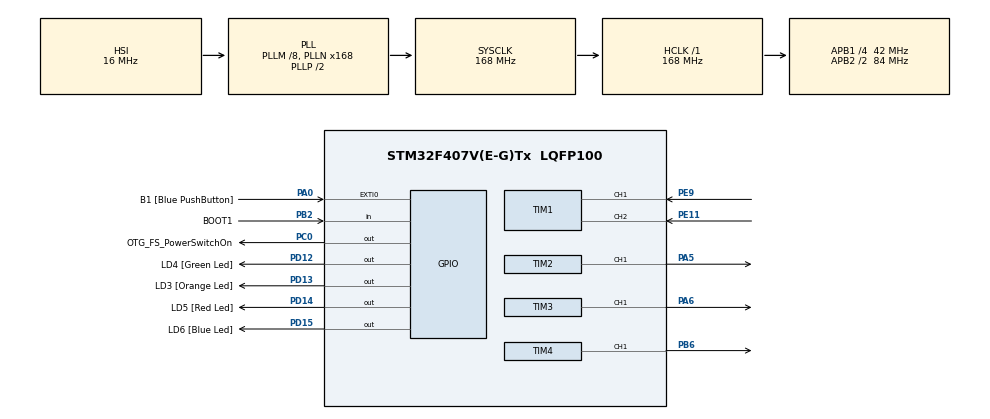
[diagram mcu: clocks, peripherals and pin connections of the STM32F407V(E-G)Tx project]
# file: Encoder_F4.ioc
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Mcu.Family=STM32F4
Mcu.Name=STM32F407V(E-G)Tx
Mcu.Package=LQFP100
NVIC.PriorityGroup=NVIC_PRIORITYGROUP_0
NVIC.TIM1_BRK_TIM9_IRQn=true\:0\:0\:false\:false\:true\:true\:true\:true
NVIC.TIM1_CC_IRQn=true\:0\:0\:false\:false\:true\:true\:true\:true
NVIC.TIM1_TRG_COM_TIM11_IRQn=true\:0\:0\:false\:false\:true\:true\:true\:true
NVIC.TIM1_UP_TIM10_IRQn=true\:0\:0\:false\:false\:true\:true\:true\:true
PA0-WKUP.GPIO_Label=B1 [Blue PushButton]
PA0-WKUP.Signal=GPXTI0
PA13.GPIO_Label=SWDIO
PA13.Signal=SYS_JTMS-SWDIO
PA14.GPIO_Label=SWCLK
PA14.Signal=SYS_JTCK-SWCLK
PA5.Signal=S_TIM2_CH1_ETR
PA6.Signal=S_TIM3_CH1
PB2.GPIO_Label=BOOT1
PB2.GPIO_Mode=GPIO_MODE_INPUT
PB2.GPIO_PuPd=GPIO_NOPULL
PB2.Signal=GPIO_Input
PB3.GPIO_Label=SWO
PB3.Signal=SYS_JTDO-SWO
PB6.Signal=S_TIM4_CH1
PC0.GPIO_Label=OTG_FS_PowerSwitchOn
PC0.GPIO_PuPd=GPIO_NOPULL
PC0.GPIO_Speed=GPIO_SPEED_FREQ_LOW
PC0.PinState=GPIO_PIN_SET
PC0.Signal=GPIO_Output
PD12.GPIO_Label=LD4 [Green Led]
PD12.GPIO_PuPd=GPIO_NOPULL
PD12.GPIO_Speed=GPIO_SPEED_FREQ_LOW
PD12.Signal=GPIO_Output
PD13.GPIO_Label=LD3 [Orange Led]
PD13.GPIO_PuPd=GPIO_NOPULL
PD13.GPIO_Speed=GPIO_SPEED_FREQ_LOW
PD13.Signal=GPIO_Output
PD14.GPIO_Label=LD5 [Red Led]
PD14.GPIO_PuPd=GPIO_NOPULL
PD14.GPIO_Speed=GPIO_SPEED_FREQ_LOW
PD14.Signal=GPIO_Output
PD15.GPIO_Label=LD6 [Blue Led]
PD15.GPIO_PuPd=GPIO_NOPULL
PD15.GPIO_Speed=GPIO_SPEED_FREQ_LOW
PD15.Signal=GPIO_Output
PE11.Signal=S_TIM1_CH2
PE9.Signal=S_TIM1_CH1
PH0-OSC_IN.GPIO_Label=PH0-OSC_IN
PH0-OSC_IN.Mode=HSE-External-Oscillator
PH0-OSC_IN.Signal=RCC_OSC_IN
PH1-OSC_OUT.GPIO_Label=PH1-OSC_OUT
PH1-OSC_OUT.Mode=HSE-External-Oscillator
PH1-OSC_OUT.Signal=RCC_OSC_OUT
ProjectManager.HeapSize=0x200
ProjectManager.StackSize=0x400
ProjectManager.TargetToolchain=STM32CubeIDE
RCC.48MHZClocksFreq_Value=48000000
RCC.AHBFreq_Value=168000000
RCC.APB1CLKDivider=RCC_HCLK_DIV4
RCC.APB1Freq_Value=42000000
RCC.APB1TimFreq_Value=84000000
RCC.APB2CLKDivider=RCC_HCLK_DIV2
RCC.APB2Freq_Value=84000000
RCC.APB2TimFreq_Value=168000000
RCC.CortexFreq_Value=168000000
RCC.HCLKFreq_Value=168000000
RCC.HSE_VALUE=8000000
RCC.HSI_VALUE=16000000
RCC.LSE_VALUE=32768
RCC.PLLM=8
RCC.PLLN=168
RCC.PLLQ=7
RCC.SYSCLKFreq_VALUE=168000000
RCC.SYSCLKSource=RCC_SYSCLKSOURCE_PLLCLK
RCC.VCOOutputFreq_Value=336000000
SH.S_TIM1_CH1.0=TIM1_CH1,Encoder_Interface
SH.S_TIM1_CH2.0=TIM1_CH2,Encoder_Interface
SH.S_TIM2_CH1_ETR.0=TIM2_CH1,PWM Generation1 CH1
SH.S_TIM3_CH1.0=TIM3_CH1,PWM Generation1 CH1
SH.S_TIM4_CH1.0=TIM4_CH1,PWM Generation1 CH1
TIM1.AutoReloadPreload=TIM_AUTORELOAD_PRELOAD_ENABLE
TIM1.EncoderMode=TIM_ENCODERMODE_TI12
TIM1.IC1Filter=10
TIM1.IC1Polarity=TIM_ICPOLARITY_FALLING
TIM1.IC2Filter=10
TIM1.IC2Polarity=TIM_ICPOLARITY_FALLING
TIM2.Channel-Output\ Compare2\ No\ Output=TIM_CHANNEL_2
TIM2.Channel-PWM\ Generation1\ CH1=TIM_CHANNEL_1
TIM2.OCMode_2=TIM_OCMODE_ACTIVE
TIM2.Period=10000-1
TIM2.Prescaler=168-1
TIM2.Pulse-Output\ Compare2\ No\ Output=2500
TIM2.Pulse-PWM\ Generation1\ CH1=5000
TIM2.TIM_MasterOutputTrigger=TIM_TRGO_OC2REF
TIM3.Channel-Output\ Compare2\ No\ Output=TIM_CHANNEL_2
TIM3.Channel-PWM\ Generation1\ CH1=TIM_CHANNEL_1
TIM3.OCMode_2=TIM_OCMODE_ACTIVE
TIM3.Period=10000-1
TIM3.Prescaler=168-1
TIM3.Pulse-Output\ Compare2\ No\ Output=2500
TIM3.Pulse-PWM\ Generation1\ CH1=5000
TIM3.TIM_MasterOutputTrigger=TIM_TRGO_OC2REF
TIM4.Channel-PWM\ Generation1\ CH1=TIM_CHANNEL_1
TIM4.Period=10000-1
TIM4.Prescaler=168-1
TIM4.Pulse-PWM\ Generation1\ CH1=5000
TIM4.TIM_MasterOutputTrigger=TIM_TRGO_RESET
VP_TIM2_VS_ClockSourceINT.Mode=Internal
VP_TIM2_VS_no_output2.Mode=Output Compare2 No Output
VP_TIM3_VS_ClockSourceITR.Mode=TriggerSource_ITR1
VP_TIM3_VS_ControllerModeTrigger.Mode=Trigger Mode
VP_TIM3_VS_no_output2.Mode=Output Compare2 No Output
VP_TIM4_VS_ClockSourceITR.Mode=TriggerSource_ITR2
VP_TIM4_VS_ControllerModeTrigger.Mode=Trigger Mode
board=STM32F407G-DISC1

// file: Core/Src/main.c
/* USER CODE BEGIN Header */
/**
  ******************************************************************************
  * @file           : main.c
  * @brief          : Main program body
  ******************************************************************************
  * @attention
  *
  * Copyright (c) 2023 STMicroelectronics.
  * All rights reserved.
  *
  * This software is licensed under terms that can be found in the LICENSE file
  * in the root directory of this software component.
  * If no LICENSE file comes with this software, it is provided AS-IS.
  *
  ******************************************************************************
  */
/* USER CODE END Header */
#include "main.h"

/* USER CODE BEGIN PD */
	uint32_t counter=0;
	int16_t count=0,position=0;
	int16_t speed=0;
/* USER CODE END PD */

TIM_HandleTypeDef htim1;
TIM_HandleTypeDef htim2;
TIM_HandleTypeDef htim3;
TIM_HandleTypeDef htim4;

void SystemClock_Config(void);
static void MX_GPIO_Init(void);
static void MX_TIM1_Init(void);
static void MX_TIM2_Init(void);
static void MX_TIM3_Init(void);
static void MX_TIM4_Init(void);
/* USER CODE BEGIN PFP */
void HAL_TIM_IC_CaptureCallback(TIM_HandleTypeDef *htim){
	counter = __HAL_TIM_GET_COUNTER(htim);
	count = (int32_t)counter;
	position = count/4;
}
/* USER CODE END PFP */

int main(void)
{

  /* MCU Configuration--------------------------------------------------------*/

  /* Reset of all peripherals, Initializes the Flash interface and the Systick. */
  HAL_Init();

  /* Configure the system clock */
  SystemClock_Config();

  /* Initialize all configured peripherals */
  MX_GPIO_Init();
  MX_TIM1_Init();
  MX_TIM2_Init();
  MX_TIM3_Init();
  MX_TIM4_Init();
  /* USER CODE BEGIN 2 */
  HAL_TIM_Encoder_Start_IT(&htim1, TIM_CHANNEL_ALL);
  HAL_TIM_PWM_Start(&htim2, TIM_CHANNEL_1);
  HAL_TIM_OC_Start(&htim2, TIM_CHANNEL_2);

  HAL_TIM_PWM_Start(&htim3, TIM_CHANNEL_1);
  HAL_TIM_OC_Start(&htim3, TIM_CHANNEL_2);

  HAL_TIM_PWM_Start(&htim4, TIM_CHANNEL_1);

  /* USER CODE END 2 */

  /* Infinite loop */
  while (1)
  {

  }
}

void SystemClock_Config(void)
{
  RCC_OscInitTypeDef RCC_OscInitStruct = {0};
  RCC_ClkInitTypeDef RCC_ClkInitStruct = {0};

  /** Configure the main internal regulator output voltage
  */
  __HAL_RCC_PWR_CLK_ENABLE();
  __HAL_PWR_VOLTAGESCALING_CONFIG(PWR_REGULATOR_VOLTAGE_SCALE1);

  /** Initializes the RCC Oscillators according to the specified parameters
  * in the RCC_OscInitTypeDef structure.
  */
  RCC_OscInitStruct.OscillatorType = RCC_OSCILLATORTYPE_HSI;
  RCC_OscInitStruct.HSIState = RCC_HSI_ON;
  RCC_OscInitStruct.HSICalibrationValue = RCC_HSICALIBRATION_DEFAULT;
  RCC_OscInitStruct.PLL.PLLState = RCC_PLL_ON;
  RCC_OscInitStruct.PLL.PLLSource = RCC_PLLSOURCE_HSI;
  RCC_OscInitStruct.PLL.PLLM = 8;
  RCC_OscInitStruct.PLL.PLLN = 168;
  RCC_OscInitStruct.PLL.PLLP = RCC_PLLP_DIV2;
  RCC_OscInitStruct.PLL.PLLQ = 7;
  if (HAL_RCC_OscConfig(&RCC_OscInitStruct) != HAL_OK)
  {
    Error_Handler();
  }

  /** Initializes the CPU, AHB and APB buses clocks
  */
  RCC_ClkInitStruct.ClockType = RCC_CLOCKTYPE_HCLK|RCC_CLOCKTYPE_SYSCLK
                              |RCC_CLOCKTYPE_PCLK1|RCC_CLOCKTYPE_PCLK2;
  RCC_ClkInitStruct.SYSCLKSource = RCC_SYSCLKSOURCE_PLLCLK;
  RCC_ClkInitStruct.AHBCLKDivider = RCC_SYSCLK_DIV1;
  RCC_ClkInitStruct.APB1CLKDivider = RCC_HCLK_DIV4;
  RCC_ClkInitStruct.APB2CLKDivider = RCC_HCLK_DIV2;

  if (HAL_RCC_ClockConfig(&RCC_ClkInitStruct, FLASH_LATENCY_5) != HAL_OK)
  {
    Error_Handler();
  }
}

static void MX_TIM1_Init(void)
{

  TIM_Encoder_InitTypeDef sConfig = {0};
  TIM_MasterConfigTypeDef sMasterConfig = {0};

  htim1.Instance = TIM1;
  htim1.Init.Prescaler = 0;
  htim1.Init.CounterMode = TIM_COUNTERMODE_UP;
  htim1.Init.Period = 65535;
  htim1.Init.ClockDivision = TIM_CLOCKDIVISION_DIV1;
  htim1.Init.RepetitionCounter = 0;
  htim1.Init.AutoReloadPreload = TIM_AUTORELOAD_PRELOAD_ENABLE;
  sConfig.EncoderMode = TIM_ENCODERMODE_TI12;
  sConfig.IC1Polarity = TIM_ICPOLARITY_FALLING;
  sConfig.IC1Selection = TIM_ICSELECTION_DIRECTTI;
  sConfig.IC1Prescaler = TIM_ICPSC_DIV1;
  sConfig.IC1Filter = 10;
  sConfig.IC2Polarity = TIM_ICPOLARITY_FALLING;
  sConfig.IC2Selection = TIM_ICSELECTION_DIRECTTI;
  sConfig.IC2Prescaler = TIM_ICPSC_DIV1;
  sConfig.IC2Filter = 10;
  if (HAL_TIM_Encoder_Init(&htim1, &sConfig) != HAL_OK)
  {
    Error_Handler();
  }
  sMasterConfig.MasterOutputTrigger = TIM_TRGO_RESET;
  sMasterConfig.MasterSlaveMode = TIM_MASTERSLAVEMODE_DISABLE;
  if (HAL_TIMEx_MasterConfigSynchronization(&htim1, &sMasterConfig) != HAL_OK)
  {
    Error_Handler();
  }

}

static void MX_TIM2_Init(void)
{

  TIM_ClockConfigTypeDef sClockSourceConfig = {0};
  TIM_MasterConfigTypeDef sMasterConfig = {0};
  TIM_OC_InitTypeDef sConfigOC = {0};

  htim2.Instance = TIM2;
  htim2.Init.Prescaler = 168-1;
  htim2.Init.CounterMode = TIM_COUNTERMODE_UP;
  htim2.Init.Period = 10000-1;
  htim2.Init.ClockDivision = TIM_CLOCKDIVISION_DIV1;
  htim2.Init.AutoReloadPreload = TIM_AUTORELOAD_PRELOAD_DISABLE;
  if (HAL_TIM_Base_Init(&htim2) != HAL_OK)
  {
    Error_Handler();
  }
  sClockSourceConfig.ClockSource = TIM_CLOCKSOURCE_INTERNAL;
  if (HAL_TIM_ConfigClockSource(&htim2, &sClockSourceConfig) != HAL_OK)
  {
    Error_Handler();
  }
  if (HAL_TIM_PWM_Init(&htim2) != HAL_OK)
  {
    Error_Handler();
  }
  if (HAL_TIM_OC_Init(&htim2) != HAL_OK)
  {
    Error_Handler();
  }
  sMasterConfig.MasterOutputTrigger = TIM_TRGO_OC2REF;
  sMasterConfig.MasterSlaveMode = TIM_MASTERSLAVEMODE_DISABLE;
  if (HAL_TIMEx_MasterConfigSynchronization(&htim2, &sMasterConfig) != HAL_OK)
  {
    Error_Handler();
  }
  sConfigOC.OCMode = TIM_OCMODE_PWM1;
  sConfigOC.Pulse = 5000;
  sConfigOC.OCPolarity = TIM_OCPOLARITY_HIGH;
  sConfigOC.OCFastMode = TIM_OCFAST_DISABLE;
  if (HAL_TIM_PWM_ConfigChannel(&htim2, &sConfigOC, TIM_CHANNEL_1) != HAL_OK)
  {
    Error_Handler();
  }
  sConfigOC.OCMode = TIM_OCMODE_ACTIVE;
  sConfigOC.Pulse = 2500;
  if (HAL_TIM_OC_ConfigChannel(&htim2, &sConfigOC, TIM_CHANNEL_2) != HAL_OK)
  {
    Error_Handler();
  }
  HAL_TIM_MspPostInit(&htim2);

}

static void MX_TIM3_Init(void)
{

  TIM_SlaveConfigTypeDef sSlaveConfig = {0};
  TIM_MasterConfigTypeDef sMasterConfig = {0};
  TIM_OC_InitTypeDef sConfigOC = {0};

  htim3.Instance = TIM3;
  htim3.Init.Prescaler = 168-1;
  htim3.Init.CounterMode = TIM_COUNTERMODE_UP;
  htim3.Init.Period = 10000-1;
  htim3.Init.ClockDivision = TIM_CLOCKDIVISION_DIV1;
  htim3.Init.AutoReloadPreload = TIM_AUTORELOAD_PRELOAD_DISABLE;
  if (HAL_TIM_Base_Init(&htim3) != HAL_OK)
  {
    Error_Handler();
  }
  if (HAL_TIM_PWM_Init(&htim3) != HAL_OK)
  {
    Error_Handler();
  }
  if (HAL_TIM_OC_Init(&htim3) != HAL_OK)
  {
    Error_Handler();
  }
  sSlaveConfig.SlaveMode = TIM_SLAVEMODE_TRIGGER;
  sSlaveConfig.InputTrigger = TIM_TS_ITR1;
  if (HAL_TIM_SlaveConfigSynchro(&htim3, &sSlaveConfig) != HAL_OK)
  {
    Error_Handler();
  }
  sMasterConfig.MasterOutputTrigger = TIM_TRGO_OC2REF;
  sMasterConfig.MasterSlaveMode = TIM_MASTERSLAVEMODE_DISABLE;
  if (HAL_TIMEx_MasterConfigSynchronization(&htim3, &sMasterConfig) != HAL_OK)
  {
    Error_Handler();
  }
  sConfigOC.OCMode = TIM_OCMODE_PWM1;
  sConfigOC.Pulse = 5000;
  sConfigOC.OCPolarity = TIM_OCPOLARITY_HIGH;
  sConfigOC.OCFastMode = TIM_OCFAST_DISABLE;
  if (HAL_TIM_PWM_ConfigChannel(&htim3, &sConfigOC, TIM_CHANNEL_1) != HAL_OK)
  {
    Error_Handler();
  }
  sConfigOC.OCMode = TIM_OCMODE_ACTIVE;
  sConfigOC.Pulse = 2500;
  if (HAL_TIM_OC_ConfigChannel(&htim3, &sConfigOC, TIM_CHANNEL_2) != HAL_OK)
  {
    Error_Handler();
  }
  HAL_TIM_MspPostInit(&htim3);

}

static void MX_TIM4_Init(void)
{

  TIM_SlaveConfigTypeDef sSlaveConfig = {0};
  TIM_MasterConfigTypeDef sMasterConfig = {0};
  TIM_OC_InitTypeDef sConfigOC = {0};

  htim4.Instance = TIM4;
  htim4.Init.Prescaler = 168-1;
  htim4.Init.CounterMode = TIM_COUNTERMODE_UP;
  htim4.Init.Period = 10000-1;
  htim4.Init.ClockDivision = TIM_CLOCKDIVISION_DIV1;
  htim4.Init.AutoReloadPreload = TIM_AUTORELOAD_PRELOAD_DISABLE;
  if (HAL_TIM_Base_Init(&htim4) != HAL_OK)
  {
    Error_Handler();
  }
  if (HAL_TIM_PWM_Init(&htim4) != HAL_OK)
  {
    Error_Handler();
  }
  sSlaveConfig.SlaveMode = TIM_SLAVEMODE_TRIGGER;
  sSlaveConfig.InputTrigger = TIM_TS_ITR2;
  if (HAL_TIM_SlaveConfigSynchro(&htim4, &sSlaveConfig) != HAL_OK)
  {
    Error_Handler();
  }
  sMasterConfig.MasterOutputTrigger = TIM_TRGO_RESET;
  sMasterConfig.MasterSlaveMode = TIM_MASTERSLAVEMODE_DISABLE;
  if (HAL_TIMEx_MasterConfigSynchronization(&htim4, &sMasterConfig) != HAL_OK)
  {
    Error_Handler();
  }
  sConfigOC.OCMode = TIM_OCMODE_PWM1;
  sConfigOC.Pulse = 5000;
  sConfigOC.OCPolarity = TIM_OCPOLARITY_HIGH;
  sConfigOC.OCFastMode = TIM_OCFAST_DISABLE;
  if (HAL_TIM_PWM_ConfigChannel(&htim4, &sConfigOC, TIM_CHANNEL_1) != HAL_OK)
  {
    Error_Handler();
  }
  HAL_TIM_MspPostInit(&htim4);

}

static void MX_GPIO_Init(void)
{
  GPIO_InitTypeDef GPIO_InitStruct = {0};

  /* GPIO Ports Clock Enable */
  __HAL_RCC_GPIOH_CLK_ENABLE();
  __HAL_RCC_GPIOC_CLK_ENABLE();
  __HAL_RCC_GPIOA_CLK_ENABLE();
  __HAL_RCC_GPIOB_CLK_ENABLE();
  __HAL_RCC_GPIOE_CLK_ENABLE();
  __HAL_RCC_GPIOD_CLK_ENABLE();

  /*Configure GPIO pin Output Level */
  HAL_GPIO_WritePin(OTG_FS_PowerSwitchOn_GPIO_Port, OTG_FS_PowerSwitchOn_Pin, GPIO_PIN_SET);

  /*Configure GPIO pin Output Level */
  HAL_GPIO_WritePin(GPIOD, LD4_Pin|LD3_Pin|LD5_Pin|LD6_Pin, GPIO_PIN_RESET);

  /*Configure GPIO pin : OTG_FS_PowerSwitchOn_Pin */
  GPIO_InitStruct.Pin = OTG_FS_PowerSwitchOn_Pin;
  GPIO_InitStruct.Mode = GPIO_MODE_OUTPUT_PP;
  GPIO_InitStruct.Pull = GPIO_NOPULL;
  GPIO_InitStruct.Speed = GPIO_SPEED_FREQ_LOW;
  HAL_GPIO_Init(OTG_FS_PowerSwitchOn_GPIO_Port, &GPIO_InitStruct);

  /*Configure GPIO pin : B1_Pin */
  GPIO_InitStruct.Pin = B1_Pin;
  GPIO_InitStruct.Mode = GPIO_MODE_IT_RISING;
  GPIO_InitStruct.Pull = GPIO_NOPULL;
  HAL_GPIO_Init(B1_GPIO_Port, &GPIO_InitStruct);

  /*Configure GPIO pin : BOOT1_Pin */
  GPIO_InitStruct.Pin = BOOT1_Pin;
  GPIO_InitStruct.Mode = GPIO_MODE_INPUT;
  GPIO_InitStruct.Pull = GPIO_NOPULL;
  HAL_GPIO_Init(BOOT1_GPIO_Port, &GPIO_InitStruct);

  /*Configure GPIO pins : LD4_Pin LD3_Pin LD5_Pin LD6_Pin */
  GPIO_InitStruct.Pin = LD4_Pin|LD3_Pin|LD5_Pin|LD6_Pin;
  GPIO_InitStruct.Mode = GPIO_MODE_OUTPUT_PP;
  GPIO_InitStruct.Pull = GPIO_NOPULL;
  GPIO_InitStruct.Speed = GPIO_SPEED_FREQ_LOW;
  HAL_GPIO_Init(GPIOD, &GPIO_InitStruct);

}

void Error_Handler(void)
{
  __disable_irq();
  while (1)
  {
  }
}
